# nrf9220_cellcore register map
Vendor: Nordic Semiconductor; Series: nRF92; File version: 1
CPU: CM33 r0p4, little endian, MPU, FPU, 3 interrupt priority bits, 480 interrupts, 8 SAU regions
Registers are 32-bit, read-write, reset 0x0 unless marked. A register's access mark holds for its fields unless they carry their own. Offsets are from the block's base; [hi:lo] are bit positions; {n}, {i} and the like mark numbered series.

## GLOBAL_MUTEX120_NS — MUTEX 0
Base 0x4F8D2000
Same registers: GLOBAL_MUTEX130_NS 0x4F927000
{0x400+4i} MUTEX[{i}] (i=0..31) — Description collection: Mutex register
  [0] MUTEX — Mutex register n
    0=Unlocked (Mutex n is in unlocked state); 1=Locked (Mutex n is in locked state)

## GLOBAL_PROTOTYPE_NS — Prototype HW information registers.
Base 0x4F8D2000; alternate view of GLOBAL_MUTEX120_NS
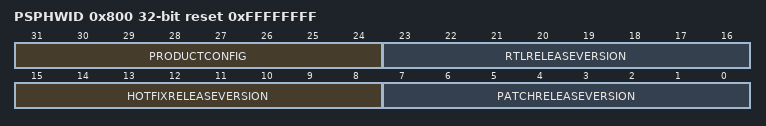
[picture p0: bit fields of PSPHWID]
0x800 PSPHWID ro reset 0xFFFFFFFF — PSP hardware ID register, unique ID for each prototype release. Used to identify RTL release that prototype is based on.
  [31:24] PRODUCTCONFIG
  [23:16] RTLRELEASEVERSION — First letter of RTL release version in ASCII corresponding to A-Z.
  [15:8] HOTFIXRELEASEVERSION
  [7:0] PATCHRELEASEVERSION — PSP patch/bugfix release version
0x804 FPGATIMESTAMP ro — 32-bit timestamp value stored by the FPGA bitstream in format ddddd_MMMM_yyyyyy_hhhhh_mmmmmm_ssssss. Unique for every FPGA netlist implementation, not dependent to RTL synthesis. 0x87654321 set in emulator database.
  [31:0] FPGATIMESTAMP — ddddd = 5 bits to represent 31 days in a month. MMMM = 4 bits to represent 12 months in a year. yyyyyy = 6 bits to represent 0 to 63 (to note year 2000 to 2063). hhhhh = 5 bits to represent 24 hours in a day. mmmmmm = 6 bits to represent 60 minutes in an hour. ssssss = 6 bits to represent 60 seconds in a minute.
0x808 EMULATORSPEEDVALUE ro — Used to store real speed of emulator is running. Used by SW to config UART speed etc, to ensure correct operation.
  [31:0] EMULATORSPEEDVALUE — Actual clock speed for FCLK 400M in emulator (Hz). In FPGA set to 0x0.
0x80C FPGACLOCKDIVIDERRATIO ro — Overall clock divider ratio for FPGA
  [31:0] FPGACLOCKDIVIDERRATIO — Overall clock divider ratio for FPGA. Set to 0 for emulator database.

## GLOBAL_AHBBUFFER_APP_NS — AHB Buffer 0
Base 0x4F90A000
Same registers: GLOBAL_AHBBUFFER_CELL_NS 0x4F90C000, GLOBAL_AHBBUFFER_APP_S 0x5F90A000, GLOBAL_AHBBUFFER_CELL_S 0x5F90C000
0x100 EVENTS_BUSERROR — Error response to posted write
  [0] EVENTS_BUSERROR
    0=NotGenerated (Event not generated); 1=Generated (Event generated)
0x200 SHORTS — Shortcuts between local events and tasks
0x300 INTEN — Enable or disable interrupt
  [0] BUSERROR — Enable or disable interrupt for event BUSERROR
    0=Disabled; 1=Enabled
0x304 INTENSET — Enable interrupt
  [0] BUSERROR — Write '1' to enable interrupt for event BUSERROR
    on read: 0=Disabled (Read: Disabled); 1=Enabled (Read: Enabled) | on write: 1=Set (Enable)
0x308 INTENCLR — Disable interrupt
  [0] BUSERROR — Write '1' to disable interrupt for event BUSERROR
    on read: 0=Disabled (Read: Disabled); 1=Enabled (Read: Enabled) | on write: 1=Clear (Disable)
0x30C INTPEND ro — Pending interrupts
  [0] BUSERROR — Read pending status of interrupt for event BUSERROR
    on read: 0=NotPending (Read: Not pending); 1=Pending (Read: Pending)
0x500 OPMODE — Operation mode
  [1:0] OPMODE
    0=f0 (Bypass); 1=f1 (Post all writes); 2=f2 (Obey hposted input); 3=f3 (Take OpMode from port)
0x504 ERRORADDRENABLE — Enable bit for error address tracking
  [0] ERRORADDRENABLE — Tracking must be enabled when it is needed. Detected error response for posted write (EVENT BUSERROR) will halt tracking and change the value of this register to 0.
    0=e0 (Error address is not tracked); 1=e1 (Error address is tracked)
0x508 ERRORADDR — Address for posted write error response
  [31:0] ERRORADDR — First address that caused error response for posted write. Valid only when EVENT BUSERROR is 1.

## GLOBAL_EGU130_NS — Event generator unit 0
Base 0x4F92D000
Same registers: GLOBAL_EGU130_S 0x5F92D000
{0x0+4i} TASKS_TRIGGER[{i}] (i=0..15) wo — Description collection: Trigger n for triggering the corresponding TRIGGERED[n] event
  [0] TASKS_TRIGGER — Trigger n for triggering the corresponding TRIGGERED[n] event
    1=Trigger task
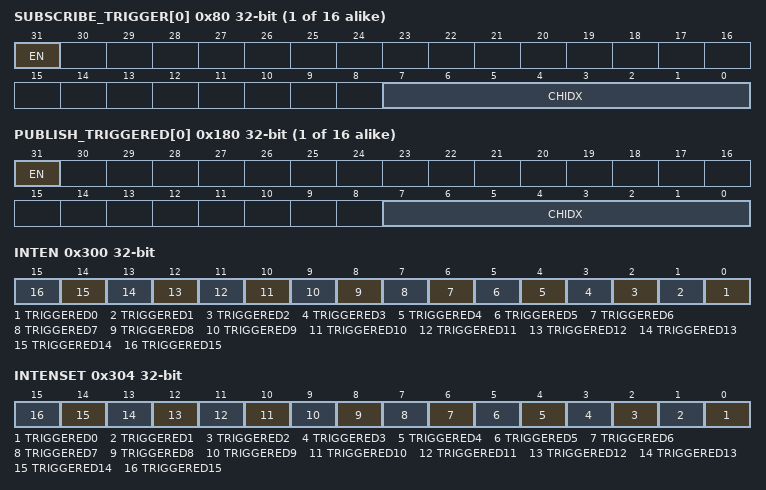
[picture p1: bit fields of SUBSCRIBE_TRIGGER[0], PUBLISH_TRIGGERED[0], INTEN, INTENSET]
{0x80+4i} SUBSCRIBE_TRIGGER[{i}] (i=0..15) — Description collection: Subscribe configuration for task TRIGGER[n]
  [31] EN
    0=Disabled (Disable subscription); 1=Enabled (Enable subscription)
  [7:0] CHIDX — DPPI channel that task TRIGGER[n] will subscribe to
{0x100+4i} EVENTS_TRIGGERED[{i}] (i=0..15) — Description collection: Event number n generated by triggering the corresponding TRIGGER[n] task
  [0] EVENTS_TRIGGERED — Event number n generated by triggering the corresponding TRIGGER[n] task
    0=NotGenerated (Event not generated); 1=Generated (Event generated)
{0x180+4i} PUBLISH_TRIGGERED[{i}] (i=0..15) — Description collection: Publish configuration for event TRIGGERED[n]
  [31] EN
    0=Disabled (Disable publishing); 1=Enabled (Enable publishing)
  [7:0] CHIDX — DPPI channel that event TRIGGERED[n] will publish to
0x300 INTEN — Enable or disable interrupt
  [all] fields
    0=Disabled; 1=Enabled
  [n] TRIGGERED{n} (n=0..15) — Enable or disable interrupt for event TRIGGERED[{n}]
0x304 INTENSET — Enable interrupt
  [all] fields
    on read: 0=Disabled (Read: Disabled); 1=Enabled (Read: Enabled) | on write: 1=Set (Enable)
  [n] TRIGGERED{n} (n=0..15) — Write '1' to enable interrupt for event TRIGGERED[{n}]
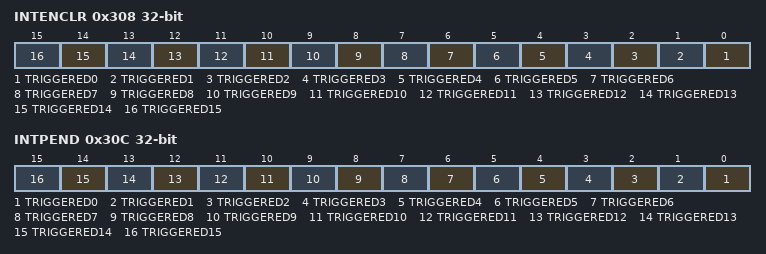
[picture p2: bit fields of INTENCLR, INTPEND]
0x308 INTENCLR — Disable interrupt
  [all] fields
    on read: 0=Disabled (Read: Disabled); 1=Enabled (Read: Enabled) | on write: 1=Clear (Disable)
  [n] TRIGGERED{n} (n=0..15) — Write '1' to disable interrupt for event TRIGGERED[{n}]
0x30C INTPEND ro — Pending interrupts
  [all] fields
    on read: 0=NotPending (Read: Not pending); 1=Pending (Read: Pending)
  [n] TRIGGERED{n} (n=0..15) — Read pending status of interrupt for event TRIGGERED[{n}]
